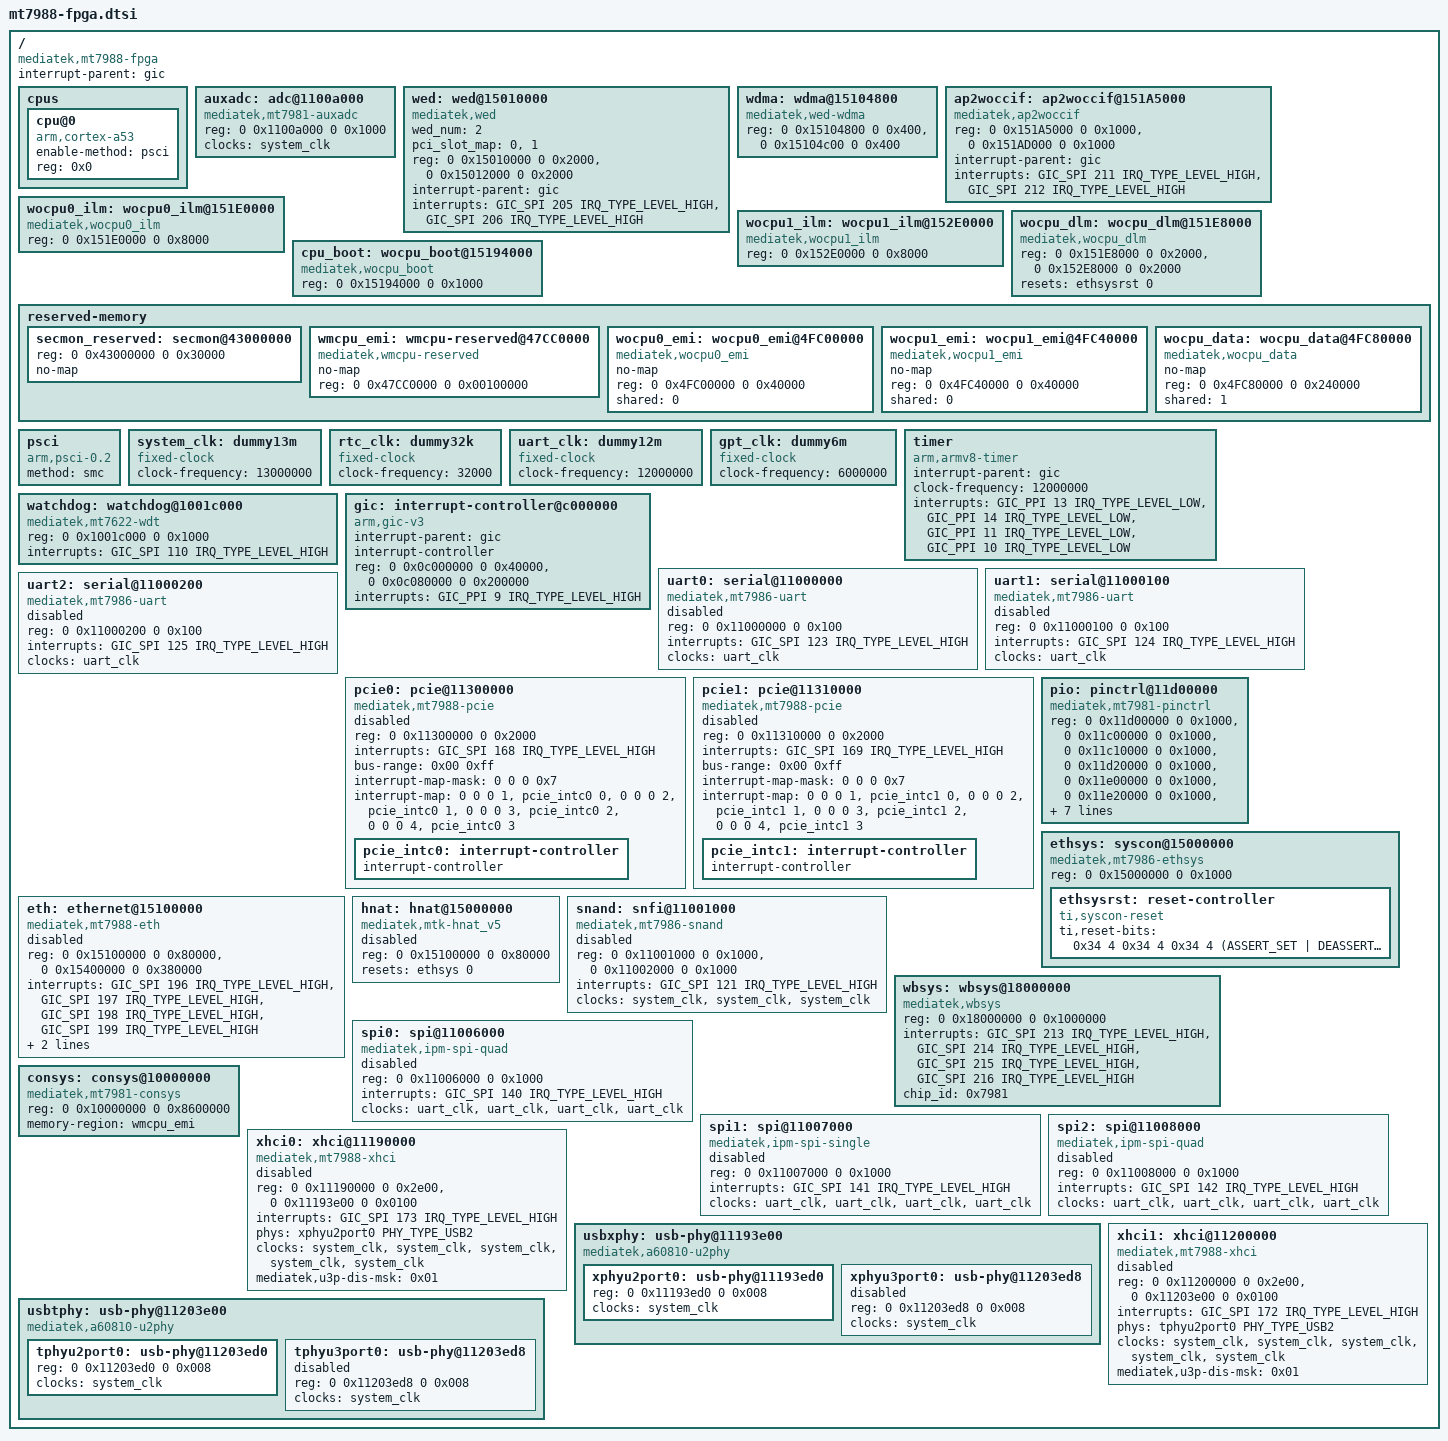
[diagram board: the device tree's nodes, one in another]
/*
 * Copyright (c) 2020 MediaTek Inc.
 * Author: Sam.Shih <sam.shih@mediatek.com>
 *
 * This program is free software; you can redistribute it and/or modify
 * it under the terms of the GNU General Public License version 2 as
 * published by the Free Software Foundation.
 *
 * This program is distributed in the hope that it will be useful,
 * but WITHOUT ANY WARRANTY; without even the implied warranty of
 * MERCHANTABILITY or FITNESS FOR A PARTICULAR PURPOSE.  See the
 * GNU General Public License for more details.
 */

#include <dt-bindings/interrupt-controller/irq.h>
#include <dt-bindings/interrupt-controller/arm-gic.h>
#include <dt-bindings/phy/phy.h>
#include <dt-bindings/reset/ti-syscon.h>
/ {
	compatible = "mediatek,mt7988-fpga";
	interrupt-parent = <&gic>;
	#address-cells = <2>;
	#size-cells = <2>;
	cpus {
		#address-cells = <1>;
		#size-cells = <0>;
		cpu@0 {
			device_type = "cpu";
			compatible = "arm,cortex-a53";
			enable-method = "psci";
			reg = <0x0>;
		};
	};

	auxadc: adc@1100a000 {
		compatible = "mediatek,mt7981-auxadc",
			     "mediatek,mt7622-auxadc";
		reg = <0 0x1100a000 0 0x1000>;
		clocks = <&system_clk>;
		clock-names = "main";
		#io-channel-cells = <1>;
	};

	wed: wed@15010000 {
		compatible = "mediatek,wed";
		wed_num = <2>;
		/* add this property for wed get the pci slot number. */
		pci_slot_map = <0>, <1>;
		reg = <0 0x15010000 0 0x2000>,
		      <0 0x15012000 0 0x2000>;
		interrupt-parent = <&gic>;
		interrupts = <GIC_SPI 205 IRQ_TYPE_LEVEL_HIGH>,
			     <GIC_SPI 206 IRQ_TYPE_LEVEL_HIGH>;
	};

	wdma: wdma@15104800 {
		compatible = "mediatek,wed-wdma";
		reg = <0 0x15104800 0 0x400>,
		      <0 0x15104c00 0 0x400>;
	};

	ap2woccif: ap2woccif@151A5000 {
		compatible = "mediatek,ap2woccif";
		reg = <0 0x151A5000 0 0x1000>,
		      <0 0x151AD000 0 0x1000>;
		interrupt-parent = <&gic>;
		interrupts = <GIC_SPI 211 IRQ_TYPE_LEVEL_HIGH>,
			     <GIC_SPI 212 IRQ_TYPE_LEVEL_HIGH>;
        };

	wocpu0_ilm: wocpu0_ilm@151E0000 {
		compatible = "mediatek,wocpu0_ilm";
		reg = <0 0x151E0000 0 0x8000>;
	};

	wocpu1_ilm: wocpu1_ilm@152E0000 {
		compatible = "mediatek,wocpu1_ilm";
		reg = <0 0x152E0000 0 0x8000>;
	};

	wocpu_dlm: wocpu_dlm@151E8000 {
		compatible = "mediatek,wocpu_dlm";
		reg = <0 0x151E8000 0 0x2000>,
		      <0 0x152E8000 0 0x2000>;

		resets = <&ethsysrst 0>;
		reset-names = "wocpu_rst";
	};

	cpu_boot: wocpu_boot@15194000 {
		compatible = "mediatek,wocpu_boot";
		reg = <0 0x15194000 0 0x1000>;
	};

	reserved-memory {
		#address-cells = <2>;
		#size-cells = <2>;
		ranges;

		/* 192 KiB reserved for ARM Trusted Firmware (BL31) */
		secmon_reserved: secmon@43000000 {
			reg = <0 0x43000000 0 0x30000>;
			no-map;
		};

		wmcpu_emi: wmcpu-reserved@47CC0000 {
			compatible = "mediatek,wmcpu-reserved";
			no-map;
			reg = <0 0x47CC0000 0 0x00100000>;
		};

		wocpu0_emi: wocpu0_emi@4FC00000 {
			compatible = "mediatek,wocpu0_emi";
			no-map;
			reg = <0 0x4FC00000 0 0x40000>;
			shared = <0>;
		};

		wocpu1_emi: wocpu1_emi@4FC40000 {
			compatible = "mediatek,wocpu1_emi";
			no-map;
			reg = <0 0x4FC40000 0 0x40000>;
			shared = <0>;
		};

		wocpu_data: wocpu_data@4FC80000 {
			compatible = "mediatek,wocpu_data";
			no-map;
			reg = <0 0x4FC80000 0 0x240000>;
			shared = <1>;
		};
	};

	psci {
		compatible  = "arm,psci-0.2";
		method      = "smc";
	};

	system_clk: dummy13m {
		compatible = "fixed-clock";
		clock-frequency = <13000000>;
		#clock-cells = <0>;
	};

	rtc_clk: dummy32k {
		compatible = "fixed-clock";
		clock-frequency = <32000>;
		#clock-cells = <0>;
	};

	uart_clk: dummy12m {
		compatible = "fixed-clock";
		clock-frequency = <12000000>;
		#clock-cells = <0>;
	};

	gpt_clk: dummy6m {
		compatible = "fixed-clock";
		clock-frequency = <6000000>;
		#clock-cells = <0>;
	};

	timer {
		compatible = "arm,armv8-timer";
		interrupt-parent = <&gic>;
		clock-frequency = <12000000>;
		interrupts = <GIC_PPI 13 IRQ_TYPE_LEVEL_LOW>,
			     <GIC_PPI 14 IRQ_TYPE_LEVEL_LOW>,
			     <GIC_PPI 11 IRQ_TYPE_LEVEL_LOW>,
			     <GIC_PPI 10 IRQ_TYPE_LEVEL_LOW>;

	};

	watchdog: watchdog@1001c000 {
		compatible = "mediatek,mt7622-wdt",
			     "mediatek,mt6589-wdt";
		reg = <0 0x1001c000 0 0x1000>;
		interrupts = <GIC_SPI 110 IRQ_TYPE_LEVEL_HIGH>;
		#reset-cells = <1>;
	};

	gic: interrupt-controller@c000000 {
		compatible = "arm,gic-v3";
		#interrupt-cells = <3>;
		interrupt-parent = <&gic>;
		interrupt-controller;
		reg = <0 0x0c000000 0 0x40000>,  /* GICD */
		      <0 0x0c080000 0 0x200000>; /* GICR */

		interrupts = <GIC_PPI 9 IRQ_TYPE_LEVEL_HIGH>;
	};

	uart0: serial@11000000 {
		compatible = "mediatek,mt7986-uart",
			     "mediatek,mt6577-uart";
		reg = <0 0x11000000 0 0x100>;
		interrupts = <GIC_SPI 123 IRQ_TYPE_LEVEL_HIGH>;
		clocks = <&uart_clk>;
		status = "disabled";
	};

	uart1: serial@11000100 {
		compatible = "mediatek,mt7986-uart",
			     "mediatek,mt6577-uart";
		reg = <0 0x11000100 0 0x100>;
		interrupts = <GIC_SPI 124 IRQ_TYPE_LEVEL_HIGH>;
		clocks = <&uart_clk>;
		status = "disabled";
	};

	uart2: serial@11000200 {
		compatible = "mediatek,mt7986-uart",
			     "mediatek,mt6577-uart";
		reg = <0 0x11000200 0 0x100>;
		interrupts = <GIC_SPI 125 IRQ_TYPE_LEVEL_HIGH>;
		clocks = <&uart_clk>;
		status = "disabled";
	};

	pcie0: pcie@11300000 {
		compatible = "mediatek,mt7988-pcie",
			     "mediatek,mt7986-pcie";
		device_type = "pci";
		#address-cells = <3>;
		#size-cells = <2>;
		reg = <0 0x11300000 0 0x2000>;
		reg-names = "pcie-mac";
		interrupts = <GIC_SPI 168 IRQ_TYPE_LEVEL_HIGH>;
		bus-range = <0x00 0xff>;
		ranges = <0x82000000 0x00 0x30000000 0x00
			  0x30000000 0x00 0x08000000>;
		status = "disabled";

		#interrupt-cells = <1>;
		interrupt-map-mask = <0 0 0 0x7>;
		interrupt-map = <0 0 0 1 &pcie_intc0 0>,
				<0 0 0 2 &pcie_intc0 1>,
				<0 0 0 3 &pcie_intc0 2>,
				<0 0 0 4 &pcie_intc0 3>;
		pcie_intc0: interrupt-controller {
			#address-cells = <0>;
			#interrupt-cells = <1>;
			interrupt-controller;
		};
	};

	pcie1: pcie@11310000 {
		compatible = "mediatek,mt7988-pcie",
			     "mediatek,mt7986-pcie";
		device_type = "pci";
		#address-cells = <3>;
		#size-cells = <2>;
		reg = <0 0x11310000 0 0x2000>;
		reg-names = "pcie-mac";
		interrupts = <GIC_SPI 169 IRQ_TYPE_LEVEL_HIGH>;
		bus-range = <0x00 0xff>;
		ranges = <0x82000000 0x00 0x38000000 0x00
			  0x38000000 0x00 0x08000000>;
		status = "disabled";

		#interrupt-cells = <1>;
		interrupt-map-mask = <0 0 0 0x7>;
		interrupt-map = <0 0 0 1 &pcie_intc1 0>,
				<0 0 0 2 &pcie_intc1 1>,
				<0 0 0 3 &pcie_intc1 2>,
				<0 0 0 4 &pcie_intc1 3>;
		pcie_intc1: interrupt-controller {
			#address-cells = <0>;
			#interrupt-cells = <1>;
			interrupt-controller;
		};
	};

	pio: pinctrl@11d00000 {
		compatible = "mediatek,mt7981-pinctrl";
		reg = <0 0x11d00000 0 0x1000>,
		      <0 0x11c00000 0 0x1000>,
		      <0 0x11c10000 0 0x1000>,
		      <0 0x11d20000 0 0x1000>,
		      <0 0x11e00000 0 0x1000>,
		      <0 0x11e20000 0 0x1000>,
		      <0 0x11f00000 0 0x1000>,
		      <0 0x11f10000 0 0x1000>,
		      <0 0x1000b000 0 0x1000>;
		reg-names = "gpio_base", "iocfg_rt_base", "iocfg_rm_base",
			    "iocfg_rb_base", "iocfg_lb_base", "iocfg_bl_base",
			    "iocfg_tm_base", "iocfg_tl_base", "eint";
		gpio-controller;
		#gpio-cells = <2>;
		gpio-ranges = <&pio 0 0 56>;
		interrupt-controller;
		interrupts = <GIC_SPI 153 IRQ_TYPE_LEVEL_HIGH>;
		interrupt-parent = <&gic>;
		#interrupt-cells = <2>;
	};

        ethsys: syscon@15000000 {
                #address-cells = <1>;
                #size-cells = <1>;
                compatible = "mediatek,mt7986-ethsys",
                             "syscon";
                reg = <0 0x15000000 0 0x1000>;
                #clock-cells = <1>;
                #reset-cells = <1>;

		ethsysrst: reset-controller {
			compatible = "ti,syscon-reset";
			#reset-cells = <1>;
			ti,reset-bits = <0x34 4 0x34 4 0x34 4 (ASSERT_SET | DEASSERT_CLEAR | STATUS_SET)>;
		};
        };

        eth: ethernet@15100000 {
		compatible = "mediatek,mt7988-eth";
		reg = <0 0x15100000 0 0x80000>,
		      <0 0x15400000 0 0x380000>;
                interrupts = <GIC_SPI 196 IRQ_TYPE_LEVEL_HIGH>,
                             <GIC_SPI 197 IRQ_TYPE_LEVEL_HIGH>,
                             <GIC_SPI 198 IRQ_TYPE_LEVEL_HIGH>,
                             <GIC_SPI 199 IRQ_TYPE_LEVEL_HIGH>;
                mediatek,ethsys = <&ethsys>;
		mediatek,infracfg = <&ethsys>;
                #reset-cells = <1>;
                #address-cells = <1>;
                #size-cells = <0>;
                status = "disabled";
        };

	hnat: hnat@15000000 {
		compatible = "mediatek,mtk-hnat_v5";
		reg = <0 0x15100000 0 0x80000>;
		resets = <&ethsys 0>;
		reset-names = "mtketh";
		status = "disabled";
	};

	snand: snfi@11001000 {
		compatible = "mediatek,mt7986-snand";
		reg = <0 0x11001000 0 0x1000>, <0 0x11002000 0 0x1000>;
		reg-names = "nfi", "ecc";
		interrupts = <GIC_SPI 121 IRQ_TYPE_LEVEL_HIGH>;
		clocks = <&system_clk>,
			 <&system_clk>,
			 <&system_clk>;
		clock-names = "nfi_clk", "pad_clk", "ecc_clk";
		#address-cells = <1>;
		#size-cells = <0>;
		status = "disabled";
	};

	wbsys: wbsys@18000000 {
		compatible = "mediatek,wbsys";
		reg = <0 0x18000000 0  0x1000000>;
		interrupts = <GIC_SPI 213 IRQ_TYPE_LEVEL_HIGH>,
					 <GIC_SPI 214 IRQ_TYPE_LEVEL_HIGH>,
					 <GIC_SPI 215 IRQ_TYPE_LEVEL_HIGH>,
					 <GIC_SPI 216 IRQ_TYPE_LEVEL_HIGH>;
		chip_id = <0x7981>;
	};

	spi0: spi@11006000 {
		compatible = "mediatek,ipm-spi-quad";
		reg = <0 0x11006000 0 0x1000>;
		interrupts = <GIC_SPI 140 IRQ_TYPE_LEVEL_HIGH>;
		clocks = <&uart_clk>,
			 <&uart_clk>,
			 <&uart_clk>,
			 <&uart_clk>;
		clock-names = "parent-clk", "sel-clk", "spi-clk", "spi-hclk";
		status = "disabled";
	};

	spi1: spi@11007000 {
		compatible = "mediatek,ipm-spi-single";
		reg = <0 0x11007000 0 0x1000>;
		interrupts = <GIC_SPI 141 IRQ_TYPE_LEVEL_HIGH>;
		clocks = <&uart_clk>,
			 <&uart_clk>,
			 <&uart_clk>,
			 <&uart_clk>;
		clock-names = "parent-clk", "sel-clk", "spi-clk", "spi-hclk";
		status = "disabled";
	};

	spi2: spi@11008000 {
		compatible = "mediatek,ipm-spi-quad";
		reg = <0 0x11008000 0 0x1000>;
		interrupts = <GIC_SPI 142 IRQ_TYPE_LEVEL_HIGH>;
		clocks = <&uart_clk>,
			 <&uart_clk>,
			 <&uart_clk>,
			 <&uart_clk>;
		clock-names = "parent-clk", "sel-clk", "spi-clk", "spi-hclk";
		status = "disabled";
	};

	consys: consys@10000000 {
		compatible = "mediatek,mt7981-consys";
		reg = <0 0x10000000 0 0x8600000>;
		memory-region = <&wmcpu_emi>;
	};

	xhci0: xhci@11190000 {
		compatible = "mediatek,mt7988-xhci",
			     "mediatek,mtk-xhci";
		reg = <0 0x11190000 0 0x2e00>,
		      <0 0x11193e00 0 0x0100>;
		reg-names = "mac", "ippc";
		interrupts = <GIC_SPI 173 IRQ_TYPE_LEVEL_HIGH>;
		phys = <&xphyu2port0 PHY_TYPE_USB2>;
		clocks = <&system_clk>,
		         <&system_clk>,
			 <&system_clk>,
			 <&system_clk>,
			 <&system_clk>;
		clock-names = "sys_ck",
			      "xhci_ck",
			      "ref_ck",
			      "mcu_ck",
			      "dma_ck";
		#address-cells = <2>;
		#size-cells = <2>;
		mediatek,u3p-dis-msk=<0x01>;
		status = "disabled";
	};

	usbxphy: usb-phy@11193e00 {
		compatible = "mediatek,a60810-u2phy",
			     "mediatek,a60931-u3phy",
			     "mediatek,a60xxx-usbphy";
		#address-cells = <2>;
		#size-cells = <2>;
		ranges;
		status = "okay";

		xphyu2port0: usb-phy@11193ed0 {
			reg = <0 0x11193ed0 0 0x008>;
			clocks = <&system_clk>;
			clock-names = "ref";
			#phy-cells = <1>;
			status = "okay";
		};

		xphyu3port0: usb-phy@11203ed8 {
			reg = <0 0x11203ed8 0 0x008>;
			clocks = <&system_clk>;
			clock-names = "ref";
			#phy-cells = <1>;
			status = "disabled";
		};
	};

	xhci1: xhci@11200000 {
		compatible = "mediatek,mt7988-xhci",
			     "mediatek,mtk-xhci";
		reg = <0 0x11200000 0 0x2e00>,
		      <0 0x11203e00 0 0x0100>;
		reg-names = "mac", "ippc";
		interrupts = <GIC_SPI 172 IRQ_TYPE_LEVEL_HIGH>;
		phys = <&tphyu2port0 PHY_TYPE_USB2>;
		clocks = <&system_clk>,
		         <&system_clk>,
			 <&system_clk>,
			 <&system_clk>,
			 <&system_clk>;
		clock-names = "sys_ck",
			      "xhci_ck",
			      "ref_ck",
			      "mcu_ck",
			      "dma_ck";
		#address-cells = <2>;
		#size-cells = <2>;
		mediatek,u3p-dis-msk=<0x01>;
		status = "disabled";
	};

	usbtphy: usb-phy@11203e00 {
		compatible = "mediatek,a60810-u2phy",
			     "mediatek,a60931-u3phy",
			     "mediatek,a60xxx-usbphy";
		#address-cells = <2>;
		#size-cells = <2>;
		ranges;
		status = "okay";

		tphyu2port0: usb-phy@11203ed0 {
			reg = <0 0x11203ed0 0 0x008>;
			clocks = <&system_clk>;
			clock-names = "ref";
			#phy-cells = <1>;
			status = "okay";
		};

		tphyu3port0: usb-phy@11203ed8 {
			reg = <0 0x11203ed8 0 0x008>;
			clocks = <&system_clk>;
			clock-names = "ref";
			#phy-cells = <1>;
			status = "disabled";
		};
	};
};
